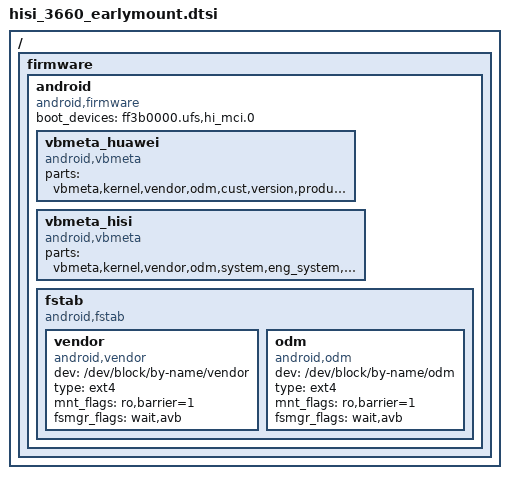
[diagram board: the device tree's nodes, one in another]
/{
	firmware {
		android {
			compatible = "android,firmware";
			boot_devices ="ff3b0000.ufs,hi_mci.0";
			vbmeta_huawei {
				compatible = "android,vbmeta";
				parts = "vbmeta,kernel,vendor,odm,cust,version,product,system,eng_system,eng_vendor,preload";
			};
			vbmeta_hisi {
				compatible = "android,vbmeta";
				parts = "vbmeta,kernel,vendor,odm,system,eng_system,eng_vendor";
			};
			fstab {
				compatible = "android,fstab";
				vendor {
					compatible = "android,vendor";
					dev = "/dev/block/by-name/vendor";
					type = "ext4";
					mnt_flags = "ro,barrier=1";
					fsmgr_flags = "wait,avb";
					status = "ok";
				};
				odm {
					compatible = "android,odm";
					dev = "/dev/block/by-name/odm";
					type = "ext4";
					mnt_flags = "ro,barrier=1";
					fsmgr_flags = "wait,avb";
					status = "ok";
				};

			};
		};
	};
};
